# R7KA8D2AD register map
Vendor: Renesas Electronics Corporation; Series: RA8; File version: 1.10.02
CPU: CM85 r0p2, little endian, MPU, FPU, VTOR, 4 interrupt priority bits, 96 interrupts
Registers are 32-bit, read-write, reset 0x0 unless marked. A register's access mark holds for its fields unless they carry their own. Offsets are from the block's base; [hi:lo] are bit positions; {n}, {i} and the like mark numbered series; 'fields as' and 'values as' point back to an identical list.

## FCACHE — SYSTEM/FLASH
Base 0x4001C100
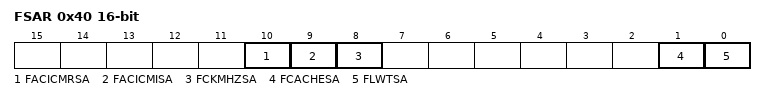
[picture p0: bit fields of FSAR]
0x40 FSAR 16-bit — Flash Security Attribution Register
  [all] fields
    0=Secure; 1=Non-secure
  [10] FACICMRSA — FACI command Registers Security Attribution
  [9] FACICMISA — FACI command Issuing Security Attribution
  [8] FCKMHZSA — FCKMHZ Security Attribution
  [1] FCACHESA — FCHACHEEN Security Attribution
  [0] FLWTSA — FLWT Security Attribution

## TCM
Base 0x4001C800
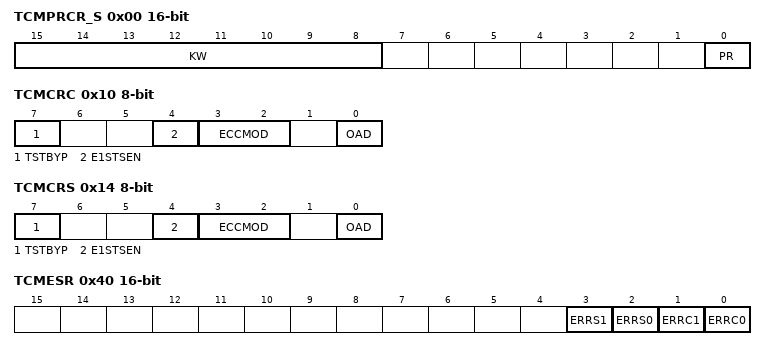
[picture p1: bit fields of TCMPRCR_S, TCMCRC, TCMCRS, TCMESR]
0x00 TCMPRCR_S 16-bit — TCM Protection Control Register for Secure
  [15:8] KW — Write Key Code
  [0] PR — Register Write Control
    0=Write registers are disabled; 1=Write registers are enabled
0x10 TCMCRC 8-bit — TCM Control Register
  [7] TSTBYP — ECC Test Enable/ECC Bypass Select
    0=Disable ECC bypass; 1=Enable ECC bypass
  [4] E1STSEN — ECC 1-Bit Error Information Update Enable
    0=Disable updating of 1-bit ECC error information; 1=Enable updating of 1-bit ECC error information
  [3:2] ECCMOD — ECC Operating Mode Select
    0=Disable ECC function; 1=Setting prohibited; 2=Enable ECC function without error checking; 3=Enable ECC function with error checking
  [0] OAD — Operation after ECC error detection
    0=Interrupt; 1=Reset
0x14 TCMCRS 8-bit — TCM Control Register
  fields as TCMCRC
0x40 TCMESR 16-bit ro — TCM Error Status Register
  [3] ERRS1 — S-TCM 2-bit ECC Error Status
    0=2-bit ECC error has not occurred; 1=2-bit ECC error has occurred
  [2] ERRS0 — S-TCM 1-bit ECC Error Status
    0=1-bit ECC error has not occurred; 1=1-bit ECC error has occurred
  [1] ERRC1 — C-TCM 2-bit ECC Error Status
    values as ERRS1
  [0] ERRC0 — C-TCM 1-bit ECC Error Status
    values as ERRS0
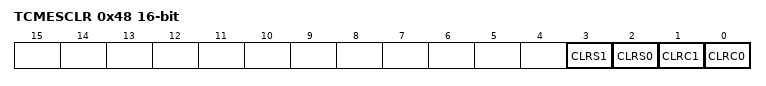
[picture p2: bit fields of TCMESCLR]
0x48 TCMESCLR 16-bit — TCM Error Status Clear Register
  [all] fields
    1=Clear error
  [3] CLRS1 — S-TCM 2-bit ECC Error Status Clear
  [2] CLRS0 — S-TCM 1-bit ECC Error Status Clear
  [1] CLRC1 — C-TCM 2-bit ECC Error Status Clear
  [0] CLRC0 — C-TCM 1-bit ECC Error Status Clear
0x50 TCMEARC0 — TCM Error Address Register
  [17:2] EAR — When an SRAM error occurs, an error address is stored.
0x54 TCMEARC1 — TCM Error Address Register
  [17:2] EAR — When an SRAM error occurs, an error address is stored.
0x58 TCMEARS0 — TCM Error Address Register
  [17:2] EAR — When an SRAM error occurs, an error address is stored.
0x5C TCMEARS1 — TCM Error Address Register
  [17:2] EAR — When an SRAM error occurs, an error address is stored.

## FACI — Flash/CPU Interface
Base 0x4011E000
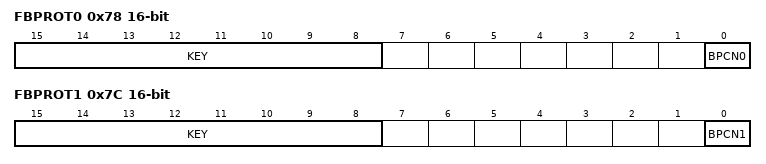
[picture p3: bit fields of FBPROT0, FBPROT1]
0x78 FBPROT0 16-bit — Flash Block Protection Register
  [15:8] KEY wo — Key Code
  [0] BPCN0 — Block Protection for Non-secure Cancel
    0=Block protection is enabled; 1=Block protection is disabled
0x7C FBPROT1 16-bit — Flash Block Protection for Secure Register
  [15:8] KEY wo — Key Code
  [0] BPCN1 — Block Protection for Secure Cancel
    values as FBPROT0.BPCN0

## ELC — Event Link Controller
Base 0x40201000
0x00 ELCR 8-bit — Event Link Controller Register
  [7] ELCON — All Event Link Enable
    0=ELC function is disabled; 1=ELC function is enabled
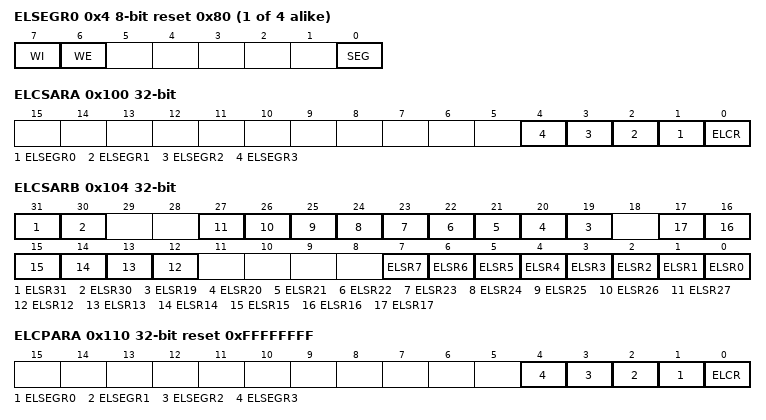
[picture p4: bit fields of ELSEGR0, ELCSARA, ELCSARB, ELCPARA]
{0x4+4i} ELSEGR{i} (i=0..3) 8-bit reset 0x80 — Event Link Software Event Generation Register {i}
  [7] WI wo — ELSEGR Register Write Disable
    0=Write to ELSEGR register enabled; 1=Write to ELSEGR register disabled
  [6] WE — SEG Bit Write Enable
    0=Write to SEG bit disabled; 1=Write to SEG bit enabled
  [0] SEG wo — Software Event Generation
    0=Normal operation; 1=Software event is generated
{0x20+4i} ELSR{i} (i=0..52) 16-bit — Event Link Setting Register {i}
  [9:0] ELS — Event Link Select
0x100 ELCSARA — Event Link Controller Security Attribution Register A
  [all] fields
    0=Secure; 1=Non-secure
  [n+1] ELSEGR{n} (n=0..3) — Event Link Software Event Generation Register {n} Security Attribution
  [0] ELCR — Event Link Controller Register Security Attribution
0x104 ELCSARB — Event Link Controller Security Attribution Register B
  [all] fields
    0=Secure; 1=Non-secure
  [31] ELSR31 — Event Link Setting Register n Security Attribution
  [30] ELSR30 — Event Link Setting Register n Security Attribution
  [n] ELSR{n} (n=19..27) — Event Link Setting Register n Security Attribution
  [n] ELSR{n} (n=12..17) — Event Link Setting Register n Security Attribution
  [n] ELSR{n} (n=0..7) — Event Link Setting Register n Security Attribution
0x108 ELCSARC — Event Link Controller Security Attribution Register C
  [20:0] ELSR — Event Link Setting Register n Security Attribution
    0=Secure; 1=Non-secure
0x110 ELCPARA reset 0xFFFFFFFF — Event Link Controller Privilege Attribution Register A
  [all] fields
    0=Privileged; 1=Unprivileged
  [n+1] ELSEGR{n} (n=0..3) — Event Link Software Event Generation Register {n} Privilege Attribution
  [0] ELCR — Event Link Controller Register Privilege Attribution
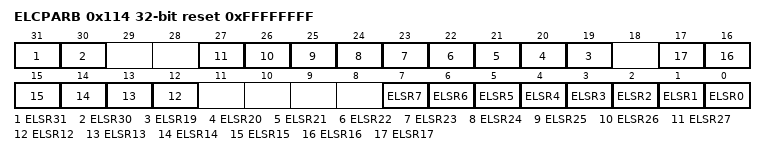
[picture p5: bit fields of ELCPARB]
0x114 ELCPARB reset 0xFFFFFFFF — Event Link Controller Privilege Attribution Register B
  [all] fields
    0=Privileged; 1=Unprivileged
  [31] ELSR31 — Event Link Setting Register n Privilege Attribution
  [30] ELSR30 — Event Link Setting Register n Privilege Attribution
  [n] ELSR{n} (n=19..27) — Event Link Setting Register n Privilege Attribution
  [n] ELSR{n} (n=12..17) — Event Link Setting Register n Privilege Attribution
  [n] ELSR{n} (n=0..7) — Event Link Setting Register n Privilege Attribution
0x118 ELCPARC reset 0xFFFFFFFF — Event Link Controller Privilege Attribution Register C
  [20:0] ELSR — Event Link Setting Register n Privilege Attribution
    0=Privileged; 1=Unprivileged
